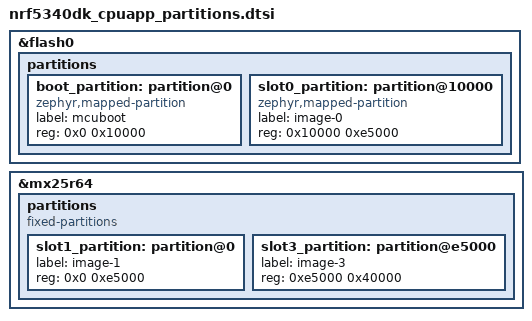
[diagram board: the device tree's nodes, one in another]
/*
 * Copyright (c) 2026 Nordic Semiconductor ASA
 *
 * SPDX-License-Identifier: LicenseRef-Nordic-5-Clause
 */

/delete-node/ &slot0_partition;

&flash0 {
	partitions {
		boot_partition: partition@0 {
			compatible = "zephyr,mapped-partition";
			label = "mcuboot";
			reg = <0x0 0x10000>;
		};

		slot0_partition: partition@10000 {
			compatible = "zephyr,mapped-partition";
			label = "image-0";
			reg = <0x10000 0xe5000>;
		};
	};
};

&mx25r64 {
	status = "okay";

	partitions {
		compatible = "fixed-partitions";
		#address-cells = <1>;
		#size-cells = <1>;

		slot1_partition: partition@0 {
			label = "image-1";
			reg = <0x0 0xe5000>;
		};

		slot3_partition: partition@e5000 {
			label = "image-3";
			reg = <0xe5000 0x40000>;
		};
	};
};
